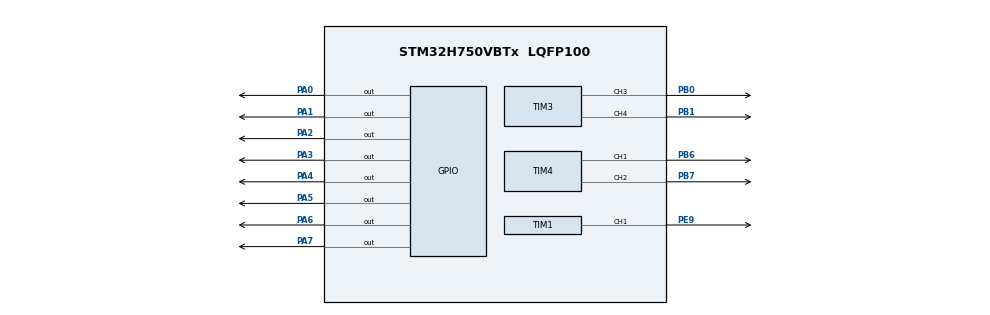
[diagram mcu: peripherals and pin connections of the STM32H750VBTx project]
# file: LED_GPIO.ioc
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CORTEX_M7.default_mode_Activation=1
Mcu.Family=STM32H7
Mcu.Name=STM32H750VBTx
Mcu.Package=LQFP100
NVIC.PriorityGroup=NVIC_PRIORITYGROUP_4
PA0.Signal=GPIO_Output
PA1.Signal=GPIO_Output
PA2.Signal=GPIO_Output
PA3.Signal=GPIO_Output
PA4.Signal=GPIO_Output
PA5.Signal=GPIO_Output
PA6.Signal=GPIO_Output
PA7.Signal=GPIO_Output
PB0.Signal=S_TIM3_CH3
PB1.Signal=S_TIM3_CH4
PB6.Signal=S_TIM4_CH1
PB7.Signal=S_TIM4_CH2
PE9.Signal=S_TIM1_CH1
ProjectManager.HeapSize=0x200
ProjectManager.StackSize=0x400
ProjectManager.TargetToolchain=CMake
RCC.ADCFreq_Value=129000000
RCC.APB1Freq_Value=64000000
RCC.APB2Freq_Value=64000000
RCC.APB3Freq_Value=64000000
RCC.APB4Freq_Value=64000000
RCC.CortexFreq_Value=64000000
RCC.HCLKFreq_Value=64000000
RCC.SYSCLKFreq_VALUE=64000000
RCC.USBFreq_Value=129000000
SH.S_TIM1_CH1.0=TIM1_CH1,PWM Generation1 CH1
SH.S_TIM3_CH3.0=TIM3_CH3,PWM Generation3 CH3
SH.S_TIM3_CH4.0=TIM3_CH4,PWM Generation4 CH4
SH.S_TIM4_CH1.0=TIM4_CH1,PWM Generation1 CH1
SH.S_TIM4_CH2.0=TIM4_CH2,PWM Generation2 CH2
TIM1.Channel-PWM\ Generation1\ CH1=TIM_CHANNEL_1
TIM1.Prescaler=1
TIM1.Pulse-PWM\ Generation1\ CH1=500
TIM3.Channel-PWM\ Generation3\ CH3=TIM_CHANNEL_3
TIM3.Channel-PWM\ Generation4\ CH4=TIM_CHANNEL_4
TIM4.Channel-PWM\ Generation1\ CH1=TIM_CHANNEL_1
TIM4.Channel-PWM\ Generation2\ CH2=TIM_CHANNEL_2
VP_MEMORYMAP_VS_MEMORYMAP.Mode=CurAppReg
board=custom

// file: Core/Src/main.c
/* USER CODE BEGIN Header */
/**
  ******************************************************************************
  * @file           : main.c
  * @brief          : Main program body
  ******************************************************************************
  * @attention
  *
  * Copyright (c) 2026 STMicroelectronics.
  * All rights reserved.
  *
  * This software is licensed under terms that can be found in the LICENSE file
  * in the root directory of this software component.
  * If no LICENSE file comes with this software, it is provided AS-IS.
  *
  ******************************************************************************
  */
/* USER CODE END Header */
#include "main.h"

TIM_HandleTypeDef htim1;
TIM_HandleTypeDef htim3;
TIM_HandleTypeDef htim4;

void SystemClock_Config(void);
static void MPU_Config(void);
static void MX_GPIO_Init(void);
static void MX_TIM1_Init(void);
static void MX_TIM3_Init(void);
static void MX_TIM4_Init(void);

/* USER CODE BEGIN 0 */
static uint32_t PWM_CompareFromPercent(TIM_HandleTypeDef *htim,
                                       uint32_t duty_percent)
{
    uint32_t period = __HAL_TIM_GET_AUTORELOAD(htim);

    if (duty_percent > 100U)
    {
        duty_percent = 100U;
    }

    return (period * duty_percent) / 100U;
}
/* USER CODE END 0 */

int main(void)
{

  /* MPU Configuration--------------------------------------------------------*/
  MPU_Config();

  /* MCU Configuration--------------------------------------------------------*/

  /* Reset of all peripherals, Initializes the Flash interface and the Systick. */
  HAL_Init();

  /* Configure the system clock */
  SystemClock_Config();

  /* Initialize all configured peripherals */
  MX_GPIO_Init();
  MX_TIM1_Init();
  MX_TIM3_Init();
  MX_TIM4_Init();
/* USER CODE BEGIN 2 */

/* Start PWM generation */

/* PB6 - TIM4 Channel 1 */
HAL_TIM_PWM_Start(&htim4, TIM_CHANNEL_1);

/* PB7 - TIM4 Channel 2 */
HAL_TIM_PWM_Start(&htim4, TIM_CHANNEL_2);

/* PB0 - TIM3 Channel 3 */
HAL_TIM_PWM_Start(&htim3, TIM_CHANNEL_3);

/* PB1 - TIM3 Channel 4 */
HAL_TIM_PWM_Start(&htim3, TIM_CHANNEL_4);

/* PE9 - TIM1 Channel 1 */
HAL_TIM_PWM_Start(&htim1, TIM_CHANNEL_1);

// /* USER CODE END 2 */
//   /* Infinite loop */
//   /* USER CODE BEGIN WHILE */
  // while (1)
  // {

//     //  ### Turn LEDs ON sequentially : PA0 to PA7 ###
// ==================================================================================
//     // for (uint16_t pin = GPIO_PIN_0; pin <= GPIO_PIN_7; pin <<= 1)
//     // {
//     //     HAL_GPIO_WritePin(GPIOA, pin, GPIO_PIN_SET);
//     //     HAL_Delay(200);
//     // }

//     // /* Turn LEDs off sequentially: PA0 to PA7 */
//     // for (uint16_t pin = GPIO_PIN_0; pin <= GPIO_PIN_7; pin <<= 1)
//     // {
//     //     HAL_GPIO_WritePin(GPIOA, pin, GPIO_PIN_RESET);
//     //     HAL_Delay(200);
//     // }
// ------------===========================-------------------------------------------
    // ### ALTERNATIVE METHOD : TogglePin syntax
    // for (uint16_t pin = GPIO_PIN_7; pin >= GPIO_PIN_0; pin >>= 1)
    // {
    //     HAL_GPIO_TogglePin(GPIOA, pin);
    //     HAL_Delay(500);
    // }

    // HAL_GPIO_WritePin(GPIOA, 0x0FF, GPIO_PIN_RESET);
    // HAL_Delay(600);

    // for (uint16_t pin = GPIO_PIN_0; pin <= GPIO_PIN_7; pin <<= 1)
    // {
    //     HAL_GPIO_TogglePin(GPIOA, pin);
    //     HAL_Delay(500);
    // }

    // HAL_GPIO_WritePin(GPIOA, 0x0FF, GPIO_PIN_RESET);
    // HAL_Delay(600);

//     //### SIMULTANEOUS ON AND OFF
    // HAL_GPIO_TogglePin(GPIOA, 0x0FF); // 0X0FF : 8'b xxxx xxxx ( 2^8 )
    // HAL_Delay (50);

//     // ==================================================================================

//   }
// }
//   /*USER CODE END WHILE*/
// =======================================================================================
/* USER CODE BEGIN WHILE */

// ======================| PWM DUTY CYCLE * TOTAL VAL |===============================
// while (1)
// {
//     /* PB0 / TIM3_CH3: 25% */
//     __HAL_TIM_SET_COMPARE(&htim3,
//                           TIM_CHANNEL_3,
//                           PWM_CompareFromPercent(&htim3, 25U));

//     /* PB1 / TIM3_CH4: 75% */
//     __HAL_TIM_SET_COMPARE(&htim3,
//                           TIM_CHANNEL_4,
//                           PWM_CompareFromPercent(&htim3, 75U));

//     HAL_Delay(1000);

//     /* PB0 / TIM3_CH3: 75% */
//     __HAL_TIM_SET_COMPARE(&htim3,
//                           TIM_CHANNEL_3,
//                           PWM_CompareFromPercent(&htim3, 75U));

//     /* PB1 / TIM3_CH4: 25% */
//     __HAL_TIM_SET_COMPARE(&htim3,
//                           TIM_CHANNEL_4,
//                           PWM_CompareFromPercent(&htim3, 25U));

//     HAL_Delay(1000);
// }

/* USER CODE BEGIN WHILE */
while (1){
  for (int timer = 0U ; timer <= 100U ; timer+=10U){

    /* PB0 / TIM3_CH3 */
    __HAL_TIM_SET_COMPARE(&htim3,
                          TIM_CHANNEL_3,
                          PWM_CompareFromPercent(&htim3, timer));

    /* PB1 / TIM3_CH4 */
    __HAL_TIM_SET_COMPARE(&htim3,
                          TIM_CHANNEL_4,
                          PWM_CompareFromPercent(&htim3, timer));

    HAL_Delay(500);
  }
}
/* USER CODE END WHILE */

}
/* USER CODE END WHILE */

//==================================================================================================
void SystemClock_Config(void)
{
  RCC_OscInitTypeDef RCC_OscInitStruct = {0};
  RCC_ClkInitTypeDef RCC_ClkInitStruct = {0};

  /** Supply configuration update enable
  */
  HAL_PWREx_ConfigSupply(PWR_LDO_SUPPLY);

  /** Configure the main internal regulator output voltage
  */
  __HAL_PWR_VOLTAGESCALING_CONFIG(PWR_REGULATOR_VOLTAGE_SCALE3);

  while(!__HAL_PWR_GET_FLAG(PWR_FLAG_VOSRDY)) {}

  /** Initializes the RCC Oscillators according to the specified parameters
  * in the RCC_OscInitTypeDef structure.
  */
  RCC_OscInitStruct.OscillatorType = RCC_OSCILLATORTYPE_HSI;
  RCC_OscInitStruct.HSIState = RCC_HSI_DIV1;
  RCC_OscInitStruct.HSICalibrationValue = RCC_HSICALIBRATION_DEFAULT;
  RCC_OscInitStruct.PLL.PLLState = RCC_PLL_NONE;
  if (HAL_RCC_OscConfig(&RCC_OscInitStruct) != HAL_OK)
  {
    Error_Handler();
  }

  /** Initializes the CPU, AHB and APB buses clocks
  */
  RCC_ClkInitStruct.ClockType = RCC_CLOCKTYPE_HCLK|RCC_CLOCKTYPE_SYSCLK
                              |RCC_CLOCKTYPE_PCLK1|RCC_CLOCKTYPE_PCLK2
                              |RCC_CLOCKTYPE_D3PCLK1|RCC_CLOCKTYPE_D1PCLK1;
  RCC_ClkInitStruct.SYSCLKSource = RCC_SYSCLKSOURCE_HSI;
  RCC_ClkInitStruct.SYSCLKDivider = RCC_SYSCLK_DIV1;
  RCC_ClkInitStruct.AHBCLKDivider = RCC_HCLK_DIV1;
  RCC_ClkInitStruct.APB3CLKDivider = RCC_APB3_DIV1;
  RCC_ClkInitStruct.APB1CLKDivider = RCC_APB1_DIV1;
  RCC_ClkInitStruct.APB2CLKDivider = RCC_APB2_DIV1;
  RCC_ClkInitStruct.APB4CLKDivider = RCC_APB4_DIV1;

  if (HAL_RCC_ClockConfig(&RCC_ClkInitStruct, FLASH_LATENCY_1) != HAL_OK)
  {
    Error_Handler();
  }
}

static void MX_TIM1_Init(void)
{

  TIM_MasterConfigTypeDef sMasterConfig = {0};
  TIM_OC_InitTypeDef sConfigOC = {0};
  TIM_BreakDeadTimeConfigTypeDef sBreakDeadTimeConfig = {0};

  htim1.Instance = TIM1;
  htim1.Init.Prescaler = 1;
  htim1.Init.CounterMode = TIM_COUNTERMODE_UP;
  htim1.Init.Period = 65535;
  htim1.Init.ClockDivision = TIM_CLOCKDIVISION_DIV1;
  htim1.Init.RepetitionCounter = 0;
  htim1.Init.AutoReloadPreload = TIM_AUTORELOAD_PRELOAD_DISABLE;
  if (HAL_TIM_PWM_Init(&htim1) != HAL_OK)
  {
    Error_Handler();
  }
  sMasterConfig.MasterOutputTrigger = TIM_TRGO_RESET;
  sMasterConfig.MasterOutputTrigger2 = TIM_TRGO2_RESET;
  sMasterConfig.MasterSlaveMode = TIM_MASTERSLAVEMODE_DISABLE;
  if (HAL_TIMEx_MasterConfigSynchronization(&htim1, &sMasterConfig) != HAL_OK)
  {
    Error_Handler();
  }
  sConfigOC.OCMode = TIM_OCMODE_PWM1;
  sConfigOC.Pulse = 500;
  sConfigOC.OCPolarity = TIM_OCPOLARITY_HIGH;
  sConfigOC.OCNPolarity = TIM_OCNPOLARITY_HIGH;
  sConfigOC.OCFastMode = TIM_OCFAST_DISABLE;
  sConfigOC.OCIdleState = TIM_OCIDLESTATE_RESET;
  sConfigOC.OCNIdleState = TIM_OCNIDLESTATE_RESET;
  if (HAL_TIM_PWM_ConfigChannel(&htim1, &sConfigOC, TIM_CHANNEL_1) != HAL_OK)
  {
    Error_Handler();
  }
  sBreakDeadTimeConfig.OffStateRunMode = TIM_OSSR_DISABLE;
  sBreakDeadTimeConfig.OffStateIDLEMode = TIM_OSSI_DISABLE;
  sBreakDeadTimeConfig.LockLevel = TIM_LOCKLEVEL_OFF;
  sBreakDeadTimeConfig.DeadTime = 0;
  sBreakDeadTimeConfig.BreakState = TIM_BREAK_DISABLE;
  sBreakDeadTimeConfig.BreakPolarity = TIM_BREAKPOLARITY_HIGH;
  sBreakDeadTimeConfig.BreakFilter = 0;
  sBreakDeadTimeConfig.Break2State = TIM_BREAK2_DISABLE;
  sBreakDeadTimeConfig.Break2Polarity = TIM_BREAK2POLARITY_HIGH;
  sBreakDeadTimeConfig.Break2Filter = 0;
  sBreakDeadTimeConfig.AutomaticOutput = TIM_AUTOMATICOUTPUT_DISABLE;
  if (HAL_TIMEx_ConfigBreakDeadTime(&htim1, &sBreakDeadTimeConfig) != HAL_OK)
  {
    Error_Handler();
  }
  HAL_TIM_MspPostInit(&htim1);

}

static void MX_TIM3_Init(void)
{

  TIM_MasterConfigTypeDef sMasterConfig = {0};
  TIM_OC_InitTypeDef sConfigOC = {0};

  htim3.Instance = TIM3;
  htim3.Init.Prescaler = 0;
  htim3.Init.CounterMode = TIM_COUNTERMODE_UP;
  htim3.Init.Period = 65535;
  htim3.Init.ClockDivision = TIM_CLOCKDIVISION_DIV1;
  htim3.Init.AutoReloadPreload = TIM_AUTORELOAD_PRELOAD_DISABLE;
  if (HAL_TIM_PWM_Init(&htim3) != HAL_OK)
  {
    Error_Handler();
  }
  sMasterConfig.MasterOutputTrigger = TIM_TRGO_RESET;
  sMasterConfig.MasterSlaveMode = TIM_MASTERSLAVEMODE_DISABLE;
  if (HAL_TIMEx_MasterConfigSynchronization(&htim3, &sMasterConfig) != HAL_OK)
  {
    Error_Handler();
  }
  sConfigOC.OCMode = TIM_OCMODE_PWM1;
  sConfigOC.Pulse = 0;
  sConfigOC.OCPolarity = TIM_OCPOLARITY_HIGH;
  sConfigOC.OCFastMode = TIM_OCFAST_DISABLE;
  if (HAL_TIM_PWM_ConfigChannel(&htim3, &sConfigOC, TIM_CHANNEL_3) != HAL_OK)
  {
    Error_Handler();
  }
  if (HAL_TIM_PWM_ConfigChannel(&htim3, &sConfigOC, TIM_CHANNEL_4) != HAL_OK)
  {
    Error_Handler();
  }
  HAL_TIM_MspPostInit(&htim3);

}

static void MX_TIM4_Init(void)
{

  TIM_MasterConfigTypeDef sMasterConfig = {0};
  TIM_OC_InitTypeDef sConfigOC = {0};

  htim4.Instance = TIM4;
  htim4.Init.Prescaler = 0;
  htim4.Init.CounterMode = TIM_COUNTERMODE_UP;
  htim4.Init.Period = 65535;
  htim4.Init.ClockDivision = TIM_CLOCKDIVISION_DIV1;
  htim4.Init.AutoReloadPreload = TIM_AUTORELOAD_PRELOAD_DISABLE;
  if (HAL_TIM_PWM_Init(&htim4) != HAL_OK)
  {
    Error_Handler();
  }
  sMasterConfig.MasterOutputTrigger = TIM_TRGO_RESET;
  sMasterConfig.MasterSlaveMode = TIM_MASTERSLAVEMODE_DISABLE;
  if (HAL_TIMEx_MasterConfigSynchronization(&htim4, &sMasterConfig) != HAL_OK)
  {
    Error_Handler();
  }
  sConfigOC.OCMode = TIM_OCMODE_PWM1;
  sConfigOC.Pulse = 0;
  sConfigOC.OCPolarity = TIM_OCPOLARITY_HIGH;
  sConfigOC.OCFastMode = TIM_OCFAST_DISABLE;
  if (HAL_TIM_PWM_ConfigChannel(&htim4, &sConfigOC, TIM_CHANNEL_1) != HAL_OK)
  {
    Error_Handler();
  }
  if (HAL_TIM_PWM_ConfigChannel(&htim4, &sConfigOC, TIM_CHANNEL_2) != HAL_OK)
  {
    Error_Handler();
  }
  HAL_TIM_MspPostInit(&htim4);

}

static void MX_GPIO_Init(void)
{
  GPIO_InitTypeDef GPIO_InitStruct = {0};

  /* GPIO Ports Clock Enable */
  __HAL_RCC_GPIOA_CLK_ENABLE();
  __HAL_RCC_GPIOB_CLK_ENABLE();
  __HAL_RCC_GPIOE_CLK_ENABLE();

  /*Configure GPIO pin Output Level */
  HAL_GPIO_WritePin(GPIOA, GPIO_PIN_0|GPIO_PIN_1|GPIO_PIN_2|GPIO_PIN_3
                          |GPIO_PIN_4|GPIO_PIN_5|GPIO_PIN_6|GPIO_PIN_7, GPIO_PIN_RESET);

  /*Configure GPIO pins : PA0 PA1 PA2 PA3
                           PA4 PA5 PA6 PA7 */
  GPIO_InitStruct.Pin = GPIO_PIN_0|GPIO_PIN_1|GPIO_PIN_2|GPIO_PIN_3
                          |GPIO_PIN_4|GPIO_PIN_5|GPIO_PIN_6|GPIO_PIN_7;
  GPIO_InitStruct.Mode = GPIO_MODE_OUTPUT_PP;
  GPIO_InitStruct.Pull = GPIO_NOPULL;
  GPIO_InitStruct.Speed = GPIO_SPEED_FREQ_LOW;
  HAL_GPIO_Init(GPIOA, &GPIO_InitStruct);

  /*AnalogSwitch Config */
  HAL_SYSCFG_AnalogSwitchConfig(SYSCFG_SWITCH_PA0, SYSCFG_SWITCH_PA0_CLOSE);

  /*AnalogSwitch Config */
  HAL_SYSCFG_AnalogSwitchConfig(SYSCFG_SWITCH_PA1, SYSCFG_SWITCH_PA1_CLOSE);

}

 /* MPU Configuration */

void MPU_Config(void)
{
  MPU_Region_InitTypeDef MPU_InitStruct = {0};

  /* Disables the MPU */
  HAL_MPU_Disable();

  /** Initializes and configures the Region and the memory to be protected
  */
  MPU_InitStruct.Enable = MPU_REGION_ENABLE;
  MPU_InitStruct.Number = MPU_REGION_NUMBER0;
  MPU_InitStruct.BaseAddress = 0x0;
  MPU_InitStruct.Size = MPU_REGION_SIZE_4GB;
  MPU_InitStruct.SubRegionDisable = 0x87;
  MPU_InitStruct.TypeExtField = MPU_TEX_LEVEL0;
  MPU_InitStruct.AccessPermission = MPU_REGION_NO_ACCESS;
  MPU_InitStruct.DisableExec = MPU_INSTRUCTION_ACCESS_DISABLE;
  MPU_InitStruct.IsShareable = MPU_ACCESS_SHAREABLE;
  MPU_InitStruct.IsCacheable = MPU_ACCESS_NOT_CACHEABLE;
  MPU_InitStruct.IsBufferable = MPU_ACCESS_NOT_BUFFERABLE;

  HAL_MPU_ConfigRegion(&MPU_InitStruct);
  /* Enables the MPU */
  HAL_MPU_Enable(MPU_PRIVILEGED_DEFAULT);

}

void Error_Handler(void)
{
  __disable_irq();
  while (1)
  {
  }
}
